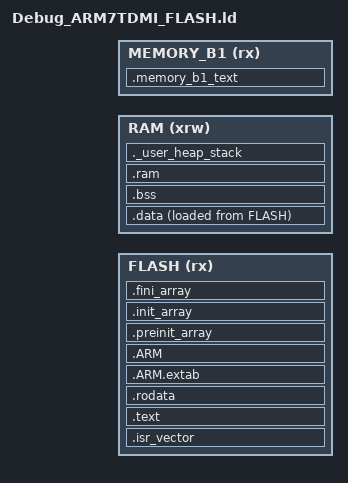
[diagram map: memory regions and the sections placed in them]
/*
*****************************************************************************
**
**  File        : template_flash.ld
**
**  Abstract    : Template linker script for generic ARM Devices.
**
**                Set heap size, stack size and stack location according
**                to application requirements.
**
**                Set memory bank area and size if external memory is used.
**
**  Target      : Generic ARM devices
**
**  Environment : Atollic TrueSTUDIO(R)
**
**  Distribution: The file is distributed "as is", without any warranty
**                of any kind.
**
**  (c)Copyright Atollic AB.
**  You may use this file as-is or modify it according to the needs of your
**  project. This file may only be built (assembled or compiled and linked)
**  using the Atollic TrueSTUDIO(R) product. The use of this file together
**  with other tools than Atollic TrueSTUDIO(R) is not permitted.
**
*****************************************************************************
*/

/* Entry Point */
ENTRY(Reset_Handler)

/* Highest address of the user mode stack */
/* Please update "0x???" according to your system requirements */
_estack = 0x???;    /* end of RAM */

FIQ_STACK_SIZE = 0x???;
IRQ_STACK_SIZE = 0x???;
ABT_STACK_SIZE = 0x???;
UND_STACK_SIZE = 0x???;
SVC_STACK_SIZE = 0x???;

/* Generate a link error if heap and stack don't fit into RAM */
/* Please update "0x???" according to your system requirements */
_Min_Heap_Size = 0x???;      /* required amount of heap  */
_Min_Stack_Size = 0x???;     /* required amount of stack */

/* Specify the memory areas */
/* Please update "0x???" according to your hardware and system requirements.
** Note! MEMORY_B1 is only needed if system requires some code/data to be 
** placed at special memory location. MEMORY_B1 specification can be removed if 
** not needed. In that case also remove MEMORY_B1 section at the end of this 
** file. Additional memory sections can also be added here.   
*/
MEMORY
{
  FLASH (rx)      : ORIGIN = 0x???, LENGTH = ???K
  RAM (xrw)       : ORIGIN = 0x???, LENGTH = ???K
  MEMORY_B1 (rx)  : ORIGIN = 0x???, LENGTH = ???K
}

/* Define output sections */
SECTIONS
{
  /* The startup code goes first into FLASH */
  .isr_vector :
  {
    . = ALIGN(4);
    KEEP(*(.isr_vector)) /* Startup code */
    . = ALIGN(4);
  } >FLASH

 /* The program code and other data goes into FLASH */
  .text :
  {
    . = ALIGN(4);
    *(.text)           /* .text sections (code) */
    *(.text*)          /* .text* sections (code) */
    *(.glue_7)         /* glue arm to thumb code */
    *(.glue_7t)        /* glue thumb to arm code */
    *(.eh_frame)

    KEEP (*(.init))
    KEEP (*(.fini))

    . = ALIGN(4);
    _etext = .;        /* define a global symbols at end of code */
  } >FLASH

  /* Constant data goes into FLASH */
  .rodata :
  {
    . = ALIGN(4);
    *(.rodata)         /* .rodata sections (constants, strings, etc.) */
    *(.rodata*)        /* .rodata* sections (constants, strings, etc.) */
    . = ALIGN(4);
  } >FLASH

  .ARM.extab   : { *(.ARM.extab* .gnu.linkonce.armextab.*) } >FLASH
  .ARM : {
    __exidx_start = .;
    *(.ARM.exidx*)
    __exidx_end = .;
  } >FLASH

  .preinit_array     :
  {
    PROVIDE_HIDDEN (__preinit_array_start = .);
    KEEP (*(.preinit_array*))
    PROVIDE_HIDDEN (__preinit_array_end = .);
  } >FLASH
  .init_array :
  {
    PROVIDE_HIDDEN (__init_array_start = .);
    KEEP (*(SORT(.init_array.*)))
    KEEP (*(.init_array*))
    PROVIDE_HIDDEN (__init_array_end = .);
  } >FLASH
  .fini_array :
  {
    PROVIDE_HIDDEN (__fini_array_start = .);
    KEEP (*(SORT(.fini_array.*)))
    KEEP (*(.fini_array*))
    PROVIDE_HIDDEN (__fini_array_end = .);
  } >FLASH

  /* used by the startup to initialize data */
  _sidata = LOADADDR(.data);

  /* Initialized data sections goes into RAM, load LMA copy after code */
  .data :
  {
    . = ALIGN(4);
    _sdata = .;        /* create a global symbol at data start */
    *(.data)           /* .data sections */
    *(.data*)          /* .data* sections */

    . = ALIGN(4);
    _edata = .;        /* define a global symbol at data end */
  } >RAM AT> FLASH

  /* Uninitialized data section */
  . = ALIGN(4);
  .bss :
  {
    /* This is used by the startup in order to initialize the .bss secion */
    _sbss = .;         /* define a global symbol at bss start */
    __bss_start__ = _sbss;
    *(.bss)
    *(.bss*)
    *(COMMON)

    . = ALIGN(4);
    _ebss = .;         /* define a global symbol at bss end */
    __bss_end__ = _ebss;
  } >RAM

  .ram :
  {
    . = ALIGN(256); 

    PROVIDE (__stack_start__ = .);
    
    PROVIDE (__stack_fiq_start__ = .);
    . += FIQ_STACK_SIZE;
    . = ALIGN(4);
    PROVIDE (__stack_fiq_end__ = .);

    PROVIDE (__stack_irq_start__ = .);
    . += IRQ_STACK_SIZE;
    . = ALIGN(4);
    PROVIDE (__stack_irq_end__ = .);

    PROVIDE (__stack_abt_start__ = .);
    . += ABT_STACK_SIZE;
    . = ALIGN(4);
    PROVIDE (__stack_abt_end__ = .);

    PROVIDE (__stack_und_start__ = .);
    . += UND_STACK_SIZE;
    . = ALIGN(4);
    PROVIDE (__stack_und_end__ = .);

    PROVIDE (__stack_svc_start__ = .);
    . += SVC_STACK_SIZE;
    . = ALIGN(4);
    PROVIDE (__stack_svc_end__ = .);
    PROVIDE (__stack_end__ = .);
    PROVIDE (__heap_start__ = .);   
  } > RAM  

  /* User_heap_stack section, used to check that there is enough RAM left */
  ._user_heap_stack :
  {
    . = ALIGN(4);
    PROVIDE ( end = . );
    PROVIDE ( _end = . );
    . = . + _Min_Heap_Size;
    . = . + _Min_Stack_Size;
    . = ALIGN(4);
  } >RAM

  /* MEMORY_bank1 section, code must be located here explicitly            */
  /* Example: extern int foo(void) __attribute__ ((section (".mb1text"))); */
  .memory_b1_text :
  {
    *(.mb1text)        /* .mb1text sections (code) */
    *(.mb1text*)       /* .mb1text* sections (code)  */
    *(.mb1rodata)      /* read-only data (constants) */
    *(.mb1rodata*)
  } >MEMORY_B1

  /* Remove information from the standard libraries */
  /DISCARD/ :
  {
    libc.a ( * )
    libm.a ( * )
    libgcc.a ( * )
  }

  .ARM.attributes 0 : { *(.ARM.attributes) }
}
